# TIMER_MODULE register map
Vendor: Texas Instruments
Peripheral module from a debugger description file (folder ucd3138064A).
Registers are 32-bit, access not given, no defined reset value unless marked. A register's access mark holds for its fields unless they carry their own. Offsets are as the file gives them; lines under a group give offsets from that group; [hi:lo] are bit positions; {n}, {i} and the like mark numbered series; 'fields as' and 'values as' point back to an identical list; <NAME> marks a mode.

## TIMER
0x00 T24CNTDAT — T24 Counter Data Register
  [23:0] CNT_DAT ro — Counter data
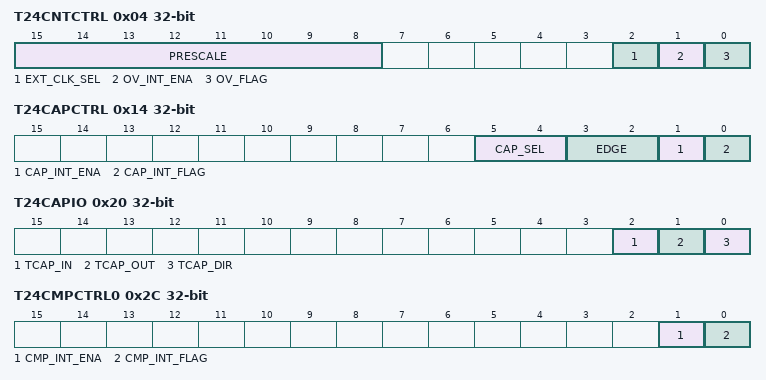
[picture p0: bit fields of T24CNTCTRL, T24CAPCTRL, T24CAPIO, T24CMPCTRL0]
0x04 T24CNTCTRL — T24 Counter Control/Status Register
  [15:8] PRESCALE rw — Prescale value
  [2] EXT_CLK_SEL rw — External clock select
  [1] OV_INT_ENA rw — Overflow interrupt enable
  [0] OV_FLAG rw — Overflow event flag
0x08 T24CAPDAT — T24 Capture Data Register
  [23:0] CAP_DAT ro — Counter data
0x14 T24CAPCTRL — T24 Capture Control Register
  [5:4] CAP_SEL rw — Capture Pin Select
  [3:2] EDGE rw — Edge select
  [1] CAP_INT_ENA rw — Capture interrupt enable
  [0] CAP_INT_FLAG rw — Capture event flag
0x20 T24CAPIO — T24 I/O Control and Data Register
  [2] TCAP_IN ro — TCAP0 pin input data
  [1] TCAP_OUT rw — TCAP0 pin output data
  [0] TCAP_DIR rw — TCAP0 pin direction
0x24 T24CMPDAT0 — T24 Compare Data Register
  [23:0] CMP_DAT rw — Compare data
0x28 T24CMPDAT1 — T24 Compare Data Register
  [23:0] CMP_DAT rw — Compare data
0x2C T24CMPCTRL0 — T24 Compare Control Register
  [1] CMP_INT_ENA rw — Compare interrupt enable
  [0] CMP_INT_FLAG rw — Compare event flag
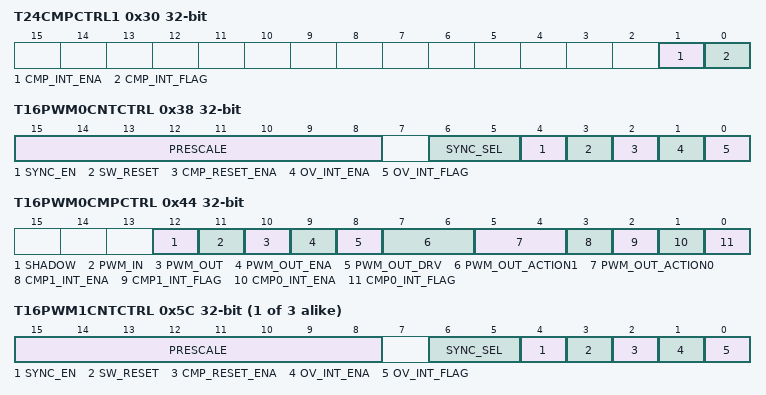
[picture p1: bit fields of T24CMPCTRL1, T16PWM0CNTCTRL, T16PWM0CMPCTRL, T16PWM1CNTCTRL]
0x30 T24CMPCTRL1 — T24 Compare Control Register
  fields as T24CMPCTRL0
0x34 T16PWM0CNTDAT — PWM0 Counter Data Register
  [15:0] CNT_DAT ro — Counter data
0x38 T16PWM0CNTCTRL — PWM0 Counter Control Register
  [15:8] PRESCALE rw — Prescale value
  [6:5] SYNC_SEL rw — Counter Sync Select
  [4] SYNC_EN rw — Counter Sync Enable
  [3] SW_RESET rw — Software reset
  [2] CMP_RESET_ENA rw — Counter reset from compare action enable
  [1] OV_INT_ENA rw — Overflow interrupt enable
  [0] OV_INT_FLAG rw — Overflow interrupt flag
0x3C T16PWM0CMP0DAT — PWM0 Compare Channel 0 Data Register
  [15:0] CMP_DAT rw — Compare data
0x40 T16PWM0CMP1DAT — PWM0 Compare Channel 1 Data Register
  [15:0] CMP_DAT rw — Compare data
0x44 T16PWM0CMPCTRL — PWM0 Compare Control Register
  [12] SHADOW rw — PWM update control
  [11] PWM_IN rw — TPWMx pin state
  [10] PWM_OUT rw — TPWMx pin output data
  [9] PWM_OUT_ENA rw — TPWMx pin output enable
  [8] PWM_OUT_DRV rw — TPMWx pin output control
  [7:6] PWM_OUT_ACTION1 rw — TPWMx pin output action on T16CMP1DR match
  [5:4] PWM_OUT_ACTION0 rw — TPWMx pin output action on T16CMP0DR match
  [3] CMP1_INT_ENA rw — Compare 1 interrupt enable
  [2] CMP1_INT_FLAG rw — Compare 1 interrupt flag
  [1] CMP0_INT_ENA rw — Compare 0 interrupt enable
  [0] CMP0_INT_FLAG rw — Compare 0 interrupt flag
{0x44+0x14*i} T16PWM{i}CNTDAT (i=1..3) — PWM{i} Counter Data Register
  [15:0] CNT_DAT ro — Counter data
{0x48+0x14*i} T16PWM{i}CNTCTRL (i=1..3) — PWM{i} Counter Control Register
  fields as T16PWM0CNTCTRL
{0x4C+0x14*i} T16PWM{i}CMP0DAT (i=1..3) — PWM{i} Compare Channel 0 Data Register
  [15:0] CMP_DAT rw — Compare data
{0x50+0x14*i} T16PWM{i}CMP1DAT (i=1..3) — PWM{i} Compare Channel 1 Data Register
  [15:0] CMP_DAT rw — Compare data
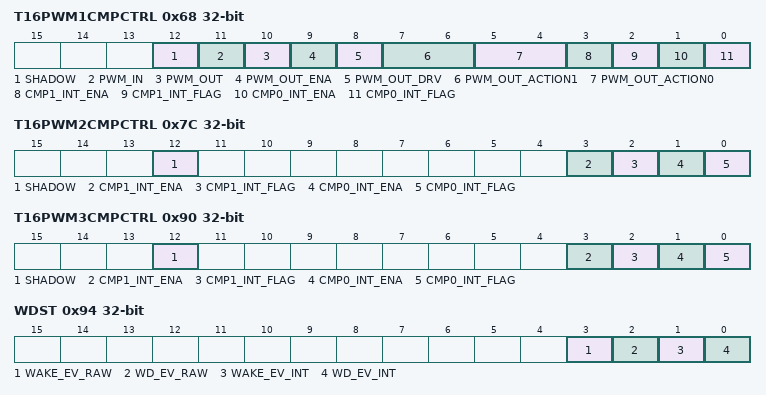
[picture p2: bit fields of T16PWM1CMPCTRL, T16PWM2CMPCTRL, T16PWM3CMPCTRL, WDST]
0x68 T16PWM1CMPCTRL — PWM1 Compare Control Register
  [12] SHADOW rw — PWM update control
  [11] PWM_IN rw — [pin=64]TPWMx pin state
  [10] PWM_OUT rw — [pin=64]TPWMx pin output data
  [9] PWM_OUT_ENA rw — [pin=64]TPWMx pin output enable
  [8] PWM_OUT_DRV rw — [pin=64]TPMWx pin output control
  [7:6] PWM_OUT_ACTION1 rw — [pin=64]TPWMx pin output action on T16CMP1DR match
  [5:4] PWM_OUT_ACTION0 rw — [pin=64]TPWMx pin output action on T16CMP0DR match
  [3] CMP1_INT_ENA rw — Compare 1 interrupt enable
  [2] CMP1_INT_FLAG rw — Compare 1 interrupt flag
  [1] CMP0_INT_ENA rw — Compare 0 interrupt enable
  [0] CMP0_INT_FLAG rw — Compare 0 interrupt flag
0x7C T16PWM2CMPCTRL — PWM2 Compare Control Register
  [12] SHADOW rw — PWM update control
  [3] CMP1_INT_ENA rw — Compare 1 interrupt enable
  [2] CMP1_INT_FLAG rw — Compare 1 interrupt flag
  [1] CMP0_INT_ENA rw — Compare 0 interrupt enable
  [0] CMP0_INT_FLAG rw — Compare 0 interrupt flag
0x90 T16PWM3CMPCTRL — PWM3 Compare Control Register
  fields as T16PWM2CMPCTRL
0x94 WDST — Watchdog Status Register
  [3] WAKE_EV_RAW ro — Watchdog Wake Event Raw Status
  [2] WD_EV_RAW ro — Watchdog Event Raw Status
  [1] WAKE_EV_INT ro — Watchdog Wake Event Interrupt Status
  [0] WD_EV_INT ro — Watchdog Event Interrupt Status
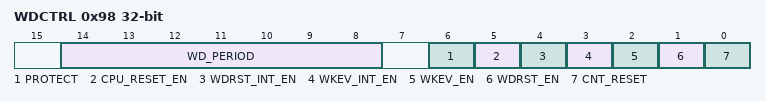
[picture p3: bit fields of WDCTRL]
0x98 WDCTRL — Watchdog Control Register
  [14:8] WD_PERIOD rw
  [6] PROTECT rw — Watchdog protect bit - active low
  [5] CPU_RESET_EN rw — WD reset of CPU enable
  [4] WDRST_INT_EN rw — WD reset event interrupt enable
  [3] WKEV_INT_EN rw — WD wake event interrupt enable
  [2] WKEV_EN rw — WD wake event enable
  [1] WDRST_EN rw — WD reset event enable
  [0] CNT_RESET rw — WD reset
